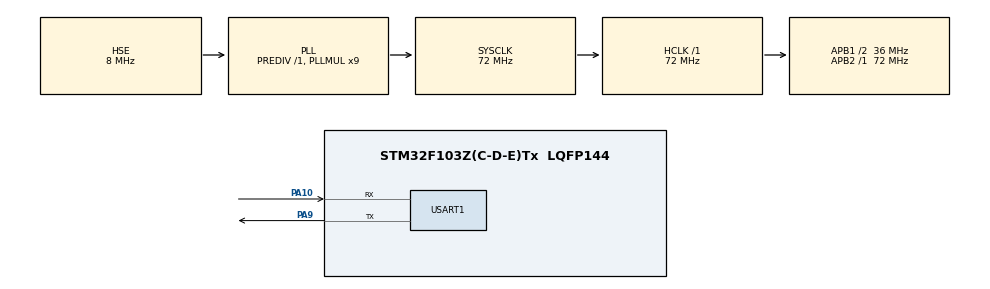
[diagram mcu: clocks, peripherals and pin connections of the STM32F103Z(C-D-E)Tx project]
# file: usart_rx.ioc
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Mcu.Family=STM32F1
Mcu.Name=STM32F103Z(C-D-E)Tx
Mcu.Package=LQFP144
NVIC.PriorityGroup=NVIC_PRIORITYGROUP_4
NVIC.USART1_IRQn=true\:0\:0\:false\:false\:true\:true\:true\:true
OSC_IN.Mode=HSE-External-Oscillator
OSC_IN.Signal=RCC_OSC_IN
OSC_OUT.Mode=HSE-External-Oscillator
OSC_OUT.Signal=RCC_OSC_OUT
PA10.Mode=Asynchronous
PA10.Signal=USART1_RX
PA13.Mode=JTAG_4_pins
PA13.Signal=SYS_JTMS-SWDIO
PA14.Mode=JTAG_4_pins
PA14.Signal=SYS_JTCK-SWCLK
PA15.Mode=JTAG_4_pins
PA15.Signal=SYS_JTDI
PA9.Mode=Asynchronous
PA9.Signal=USART1_TX
PB3.Mode=JTAG_4_pins
PB3.Signal=SYS_JTDO-TRACESWO
PC14-OSC32_IN.Mode=LSE-External-Oscillator
PC14-OSC32_IN.Signal=RCC_OSC32_IN
PC15-OSC32_OUT.Mode=LSE-External-Oscillator
PC15-OSC32_OUT.Signal=RCC_OSC32_OUT
ProjectManager.HeapSize=0x200
ProjectManager.StackSize=0x400
ProjectManager.TargetToolchain=STM32CubeIDE
RCC.AHBFreq_Value=72000000
RCC.APB1CLKDivider=RCC_HCLK_DIV2
RCC.APB1Freq_Value=36000000
RCC.APB1TimFreq_Value=72000000
RCC.APB2Freq_Value=72000000
RCC.APB2TimFreq_Value=72000000
RCC.HCLKFreq_Value=72000000
RCC.PLLMUL=RCC_PLL_MUL9
RCC.PLLSourceVirtual=RCC_PLLSOURCE_HSE
RCC.RTCClockSelection=RCC_RTCCLKSOURCE_LSE
RCC.SYSCLKFreq_VALUE=72000000
RCC.SYSCLKSource=RCC_SYSCLKSOURCE_PLLCLK
RCC.USBFreq_Value=72000000
USART1.VirtualMode=VM_ASYNC
VP_RTC_VS_RTC_Activate.Mode=RTC_Enabled
board=custom

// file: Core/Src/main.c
/* USER CODE BEGIN Header */
/**
 ******************************************************************************
 * @file           : main.c
 * @brief          : Main program body
 ******************************************************************************
 * @attention
 *
 * Copyright (c) 2022 STMicroelectronics.
 * All rights reserved.
 *
 * This software is licensed under terms that can be found in the LICENSE file
 * in the root directory of this software component.
 * If no LICENSE file comes with this software, it is provided AS-IS.
 *
 ******************************************************************************
 */
/* USER CODE END Header */
#include "main.h"
#include <string.h>
#include <stdarg.h>

/* USER CODE BEGIN PTD */
//@ref:https://github.com/mpredfearn/simple-printf
int putchar(int c);
static void simple_outputchar(char **str, char c) {
	if (str) {
		**str = c;
		++(*str);
	} else {
		putchar(c);
	}
}

enum flags {
	PAD_ZERO = 1, PAD_RIGHT = 2,
};

static int prints(char **out, const char *string, int width, int flags) {
	int pc = 0, padchar = ' ';

	if (width > 0) {
		int len = 0;
		const char *ptr;
		for (ptr = string; *ptr; ++ptr)
			++len;
		if (len >= width)
			width = 0;
		else
			width -= len;
		if (flags & PAD_ZERO)
			padchar = '0';
	}
	if (!(flags & PAD_RIGHT)) {
		for (; width > 0; --width) {
			simple_outputchar(out, padchar);
			++pc;
		}
	}
	for (; *string; ++string) {
		simple_outputchar(out, *string);
		++pc;
	}
	for (; width > 0; --width) {
		simple_outputchar(out, padchar);
		++pc;
	}

	return pc;
}

#define PRINT_BUF_LEN 64

static int simple_outputi(char **out, long long i, int base, int sign,
		int width, int flags, int letbase) {
	char print_buf[PRINT_BUF_LEN];
	char *s;
	int t, neg = 0, pc = 0;
	unsigned long long u = i;

	if (i == 0) {
		print_buf[0] = '0';
		print_buf[1] = '\0';
		return prints(out, print_buf, width, flags);
	}

	if (sign && base == 10 && i < 0) {
		neg = 1;
		u = -i;
	}

	s = print_buf + PRINT_BUF_LEN - 1;
	*s = '\0';

	while (u) {
		t = u % base;
		if (t >= 10)
			t += letbase - '0' - 10;
		*--s = t + '0';
		u /= base;
	}

	if (neg) {
		if (width && (flags & PAD_ZERO)) {
			simple_outputchar(out, '-');
			++pc;
			--width;
		} else {
			*--s = '-';
		}
	}

	return pc + prints(out, s, width, flags);
}

static int simple_vsprintf(char **out, char *format, va_list ap) {
	int width, flags;
	int pc = 0;
	char scr[2];
	union {
		char c;
		char *s;
		int i;
		unsigned int u;
		long li;
		unsigned long lu;
		long long lli;
		unsigned long long llu;
		short hi;
		unsigned short hu;
		signed char hhi;
		unsigned char hhu;
		void *p;
	} u;

	for (; *format != 0; ++format) {
		if (*format == '%') {
			++format;
			width = flags = 0;
			if (*format == '\0')
				break;
			if (*format == '%')
				goto out;
			if (*format == '-') {
				++format;
				flags = PAD_RIGHT;
			}
			while (*format == '0') {
				++format;
				flags |= PAD_ZERO;
			}
			if (*format == '*') {
				width = va_arg(ap, int);
				format++;
			} else {
				for (; *format >= '0' && *format <= '9'; ++format) {
					width *= 10;
					width += *format - '0';
				}
			}
			switch (*format) {
			case ('d'):
				u.i = va_arg(ap, int);
				pc += simple_outputi(out, u.i, 10, 1, width, flags, 'a');
				break;

			case ('u'):
				u.u = va_arg(ap, unsigned int);
				pc += simple_outputi(out, u.u, 10, 0, width, flags, 'a');
				break;

			case ('x'):
				u.u = va_arg(ap, unsigned int);
				pc += simple_outputi(out, u.u, 16, 0, width, flags, 'a');
				break;

			case ('X'):
				u.u = va_arg(ap, unsigned int);
				pc += simple_outputi(out, u.u, 16, 0, width, flags, 'A');
				break;

			case ('c'):
				u.c = va_arg(ap, int);
				scr[0] = u.c;
				scr[1] = '\0';
				pc += prints(out, scr, width, flags);
				break;

			case ('s'):
				u.s = va_arg(ap, char *);
				pc += prints(out, u.s ? u.s : "(null)", width, flags);
				break;
			case ('l'):
				++format;
				switch (*format) {
				case ('d'):
					u.li = va_arg(ap, long);
					pc += simple_outputi(out, u.li, 10, 1, width, flags, 'a');
					break;

				case ('u'):
					u.lu = va_arg(ap, unsigned long);
					pc += simple_outputi(out, u.lu, 10, 0, width, flags, 'a');
					break;

				case ('x'):
					u.lu = va_arg(ap, unsigned long);
					pc += simple_outputi(out, u.lu, 16, 0, width, flags, 'a');
					break;

				case ('X'):
					u.lu = va_arg(ap, unsigned long);
					pc += simple_outputi(out, u.lu, 16, 0, width, flags, 'A');
					break;

				case ('l'):
					++format;
					switch (*format) {
					case ('d'):
						u.lli = va_arg(ap, long long);
						pc += simple_outputi(out, u.lli, 10, 1, width, flags,
								'a');
						break;

					case ('u'):
						u.llu = va_arg(ap, unsigned long long);
						pc += simple_outputi(out, u.llu, 10, 0, width, flags,
								'a');
						break;

					case ('x'):
						u.llu = va_arg(ap, unsigned long long);
						pc += simple_outputi(out, u.llu, 16, 0, width, flags,
								'a');
						break;

					case ('X'):
						u.llu = va_arg(ap, unsigned long long);
						pc += simple_outputi(out, u.llu, 16, 0, width, flags,
								'A');
						break;

					default:
						break;
					}
					break;
				default:
					break;
				}
				break;
			case ('h'):
				++format;
				switch (*format) {
				case ('d'):
					u.hi = va_arg(ap, int);
					pc += simple_outputi(out, u.hi, 10, 1, width, flags, 'a');
					break;

				case ('u'):
					u.hu = va_arg(ap, unsigned int);
					pc += simple_outputi(out, u.lli, 10, 0, width, flags, 'a');
					break;

				case ('x'):
					u.hu = va_arg(ap, unsigned int);
					pc += simple_outputi(out, u.lli, 16, 0, width, flags, 'a');
					break;

				case ('X'):
					u.hu = va_arg(ap, unsigned int);
					pc += simple_outputi(out, u.lli, 16, 0, width, flags, 'A');
					break;

				case ('h'):
					++format;
					switch (*format) {
					case ('d'):
						u.hhi = va_arg(ap, int);
						pc += simple_outputi(out, u.hhi, 10, 1, width, flags,
								'a');
						break;

					case ('u'):
						u.hhu = va_arg(ap, unsigned int);
						pc += simple_outputi(out, u.lli, 10, 0, width, flags,
								'a');
						break;

					case ('x'):
						u.hhu = va_arg(ap, unsigned int);
						pc += simple_outputi(out, u.lli, 16, 0, width, flags,
								'a');
						break;

					case ('X'):
						u.hhu = va_arg(ap, unsigned int);
						pc += simple_outputi(out, u.lli, 16, 0, width, flags,
								'A');
						break;

					default:
						break;
					}
					break;
				default:
					break;
				}
				break;
			default:
				break;
			}
		} else {
			out: simple_outputchar(out, *format);
			++pc;
		}
	}
	if (out)
		**out = '\0';
	return pc;
}

int simple_printf(char *fmt, ...) {
	va_list ap;
	int r;

	va_start(ap, fmt);
	r = simple_vsprintf(NULL, fmt, ap);
	va_end(ap);

	return r;
}

int simple_sprintf(char *buf, char *fmt, ...) {
	va_list ap;
	int r;

	va_start(ap, fmt);
	r = simple_vsprintf(&buf, fmt, ap);
	va_end(ap);

	return r;
}

/* USER CODE END PTD */

/* USER CODE BEGIN PM */
#define UART_BUFFER_SIZE  (256) 		//最大接收字节数
/* USER CODE END PM */

RTC_HandleTypeDef hrtc;

UART_HandleTypeDef huart1;

/* USER CODE BEGIN PV */
char uart1_rx_buf[UART_BUFFER_SIZE];   	//接收数据
uint8_t uart1_rx_cnt = 0;				//接收缓冲计数
uint8_t uart1_rx_data = 0;				//接收中断缓冲
/* USER CODE END PV */

void SystemClock_Config(void);
static void MX_GPIO_Init(void);
static void MX_RTC_Init(void);
static void MX_USART1_UART_Init(void);

/* USER CODE BEGIN 0 */
int putchar(int c) {
	HAL_UART_Transmit(&huart1, &c, 1, 10);
	return c;
}
/* USER CODE END 0 */

int main(void) {

	/* MCU Configuration--------------------------------------------------------*/

	/* Reset of all peripherals, Initializes the Flash interface and the Systick. */
	HAL_Init();

	/* Configure the system clock */
	SystemClock_Config();

	/* Initialize all configured peripherals */
	MX_GPIO_Init();
	MX_RTC_Init();
	MX_USART1_UART_Init();
	/* USER CODE BEGIN 2 */
	HAL_UART_Receive_IT(&huart1, (uint8_t*) &uart1_rx_data, 1);
	/* USER CODE END 2 */

	/* Infinite loop */
	while (1) {

	}
}

void SystemClock_Config(void) {
	RCC_OscInitTypeDef RCC_OscInitStruct = { 0 };
	RCC_ClkInitTypeDef RCC_ClkInitStruct = { 0 };
	RCC_PeriphCLKInitTypeDef PeriphClkInit = { 0 };

	/** Initializes the RCC Oscillators according to the specified parameters
	 * in the RCC_OscInitTypeDef structure.
	 */
	RCC_OscInitStruct.OscillatorType = RCC_OSCILLATORTYPE_HSE
			| RCC_OSCILLATORTYPE_LSE;
	RCC_OscInitStruct.HSEState = RCC_HSE_ON;
	RCC_OscInitStruct.HSEPredivValue = RCC_HSE_PREDIV_DIV1;
	RCC_OscInitStruct.LSEState = RCC_LSE_ON;
	RCC_OscInitStruct.HSIState = RCC_HSI_ON;
	RCC_OscInitStruct.PLL.PLLState = RCC_PLL_ON;
	RCC_OscInitStruct.PLL.PLLSource = RCC_PLLSOURCE_HSE;
	RCC_OscInitStruct.PLL.PLLMUL = RCC_PLL_MUL9;
	if (HAL_RCC_OscConfig(&RCC_OscInitStruct) != HAL_OK) {
		Error_Handler();
	}

	/** Initializes the CPU, AHB and APB buses clocks
	 */
	RCC_ClkInitStruct.ClockType = RCC_CLOCKTYPE_HCLK | RCC_CLOCKTYPE_SYSCLK
			| RCC_CLOCKTYPE_PCLK1 | RCC_CLOCKTYPE_PCLK2;
	RCC_ClkInitStruct.SYSCLKSource = RCC_SYSCLKSOURCE_PLLCLK;
	RCC_ClkInitStruct.AHBCLKDivider = RCC_SYSCLK_DIV1;
	RCC_ClkInitStruct.APB1CLKDivider = RCC_HCLK_DIV2;
	RCC_ClkInitStruct.APB2CLKDivider = RCC_HCLK_DIV1;

	if (HAL_RCC_ClockConfig(&RCC_ClkInitStruct, FLASH_LATENCY_2) != HAL_OK) {
		Error_Handler();
	}
	PeriphClkInit.PeriphClockSelection = RCC_PERIPHCLK_RTC;
	PeriphClkInit.RTCClockSelection = RCC_RTCCLKSOURCE_LSE;
	if (HAL_RCCEx_PeriphCLKConfig(&PeriphClkInit) != HAL_OK) {
		Error_Handler();
	}
}

static void MX_RTC_Init(void) {

	/** Initialize RTC Only
	 */
	hrtc.Instance = RTC;
	hrtc.Init.AsynchPrediv = RTC_AUTO_1_SECOND;
	hrtc.Init.OutPut = RTC_OUTPUTSOURCE_ALARM;
	if (HAL_RTC_Init(&hrtc) != HAL_OK) {
		Error_Handler();
	}

}

static void MX_USART1_UART_Init(void) {

	huart1.Instance = USART1;
	huart1.Init.BaudRate = 115200;
	huart1.Init.WordLength = UART_WORDLENGTH_8B;
	huart1.Init.StopBits = UART_STOPBITS_1;
	huart1.Init.Parity = UART_PARITY_NONE;
	huart1.Init.Mode = UART_MODE_TX_RX;
	huart1.Init.HwFlowCtl = UART_HWCONTROL_NONE;
	huart1.Init.OverSampling = UART_OVERSAMPLING_16;
	if (HAL_UART_Init(&huart1) != HAL_OK) {
		Error_Handler();
	}

}

static void MX_GPIO_Init(void) {

	/* GPIO Ports Clock Enable */
	__HAL_RCC_GPIOC_CLK_ENABLE();
	__HAL_RCC_GPIOA_CLK_ENABLE();
	__HAL_RCC_GPIOB_CLK_ENABLE();

}

/* USER CODE BEGIN 4 */
void HAL_UART_RxCpltCallback(UART_HandleTypeDef *huart) {
	/* Prevent unused argument(s) compilation warning */
	UNUSED(huart);
	/* NOTE: This function Should not be modified, when the callback is needed,
	 the HAL_UART_TxCpltCallback could be implemented in the user file
	 */
	if (huart->Instance == USART1) {
		if (uart1_rx_cnt == 255) {
			simple_printf("%s\n", uart1_rx_buf);
			memset(uart1_rx_buf, 0x00, sizeof(uart1_rx_buf));
			uart1_rx_cnt = 0;
			uart1_rx_buf[uart1_rx_cnt++] = uart1_rx_data;
		} else {
			uart1_rx_buf[uart1_rx_cnt++] = uart1_rx_data;
			if ((uart1_rx_buf[uart1_rx_cnt - 1] == 0x0A)
					&& (uart1_rx_buf[uart1_rx_cnt - 2] == 0x0D)) {
				simple_printf("%s\n", uart1_rx_buf);
				uart1_rx_cnt = 0;
				memset(uart1_rx_buf, 0x00, sizeof(uart1_rx_buf));
			}
		}
		HAL_UART_Receive_IT(&huart1, (uint8_t*) &uart1_rx_data, 1);
	}

}
/* USER CODE END 4 */

void Error_Handler(void) {
	__disable_irq();
	while (1) {
	}
}
